# CC3200 register map
Vendor: Texas Instruments; Series: SimpleLink; File version: 1.0
CPU: CM4 r0p1, little endian, MPU, no FPU, 3 interrupt priority bits
Registers are 32-bit, read-write, reset 0x0 unless marked. A register's access mark holds for its fields unless they carry their own. Offsets are from the block's base; [hi:lo] are bit positions; {n}, {i} and the like mark numbered series.

## SHAMD5
Base 0x44035000
0x00 ODIGEST_A — SHAMD5_ODIGEST_A
  [31:0] DATA_M
0x04 ODIGEST_B — SHAMD5_ODIGEST_B
  [31:0] DATA_M
0x08 ODIGEST_C — SHAMD5_ODIGEST_C
  [31:0] DATA_M
0x0C ODIGEST_D — SHAMD5_ODIGEST_D
  [31:0] DATA_M
0x10 ODIGEST_E — SHAMD5_ODIGEST_E
  [31:0] DATA_M
0x14 ODIGEST_F — SHAMD5_ODIGEST_F
  [31:0] DATA_M
0x18 ODIGEST_G — SHAMD5_ODIGEST_G
  [31:0] DATA_M
0x1C ODIGEST_H — SHAMD5_ODIGEST_H
  [31:0] DATA_M
0x20 IDIGEST_A — SHAMD5_IDIGEST_A
  [31:0] DATA_M
0x24 IDIGEST_B — SHAMD5_IDIGEST_B
  [31:0] DATA_M
0x28 IDIGEST_C — SHAMD5_IDIGEST_C
  [31:0] DATA_M
0x2C IDIGEST_D — SHAMD5_IDIGEST_D
  [31:0] DATA_M
0x30 IDIGEST_E — SHAMD5_IDIGEST_E
  [31:0] DATA_M
0x34 IDIGEST_F — SHAMD5_IDIGEST_F
  [31:0] DATA_M
0x38 IDIGEST_G — SHAMD5_IDIGEST_G
  [31:0] DATA_M
0x3C IDIGEST_H — SHAMD5_IDIGEST_H
  [31:0] DATA_M
0x40 DIGEST_COUNT — SHAMD5_DIGEST_COUNT
  [31:0] DATA_M
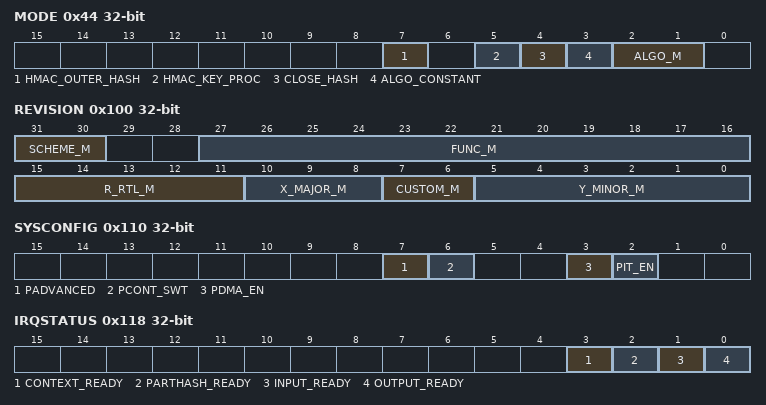
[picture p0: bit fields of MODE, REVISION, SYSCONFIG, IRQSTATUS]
0x44 MODE — SHAMD5_MODE
  [7] HMAC_OUTER_HASH — SHAMD5_MODE
  [5] HMAC_KEY_PROC — SHAMD5_MODE
  [4] CLOSE_HASH — SHAMD5_MODE
  [3] ALGO_CONSTANT — SHAMD5_MODE
  [2:1] ALGO_M — SHAMD5_MODE
0x48 LENGTH — SHAMD5_LENGTH
  [31:0] DATA_M
{0x80+4i} DATA{i}_IN (i=0..15) — SHAMD5_DATA{i}_IN
  [31:0] DATA{i}_IN_M
0x100 REVISION — SHAMD5_REVISION
  [31:30] SCHEME_M — SHAMD5_REVISION
  [27:16] FUNC_M — SHAMD5_REVISION
  [15:11] R_RTL_M — SHAMD5_REVISION
  [10:8] X_MAJOR_M — SHAMD5_REVISION
  [7:6] CUSTOM_M — SHAMD5_REVISION
  [5:0] Y_MINOR_M — SHAMD5_REVISION
0x110 SYSCONFIG — SHAMD5_SYSCONFIG
  [7] PADVANCED — SHAMD5_SYSCONFIG
  [6] PCONT_SWT — SHAMD5_SYSCONFIG
  [3] PDMA_EN — SHAMD5_SYSCONFIG
  [2] PIT_EN — SHAMD5_SYSCONFIG
0x114 SYSSTATUS — SHAMD5_SYSSTATUS
  [0] RESETDONE
0x118 IRQSTATUS — SHAMD5_IRQSTATUS
  [3] CONTEXT_READY — SHAMD5_IRQSTATUS
  [2] PARTHASH_READY — SHAMD5_IRQSTATUS
  [1] INPUT_READY — SHAMD5_IRQSTATUS
  [0] OUTPUT_READY — SHAMD5_IRQSTATUS
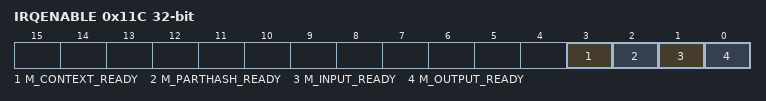
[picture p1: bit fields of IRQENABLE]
0x11C IRQENABLE — SHAMD5_IRQENABLE
  [3] M_CONTEXT_READY — SHAMD5_IRQENABLE
  [2] M_PARTHASH_READY — SHAMD5_IRQENABLE
  [1] M_INPUT_READY — SHAMD5_IRQENABLE
  [0] M_OUTPUT_READY — SHAMD5_IRQENABLE
0x200 HASH512_ODIGEST_A — SHAMD5_HASH512_ODIGEST_A
  [31:0] DATA_M
0x204 HASH512_ODIGEST_B — SHAMD5_HASH512_ODIGEST_B
  [31:0] DATA_M
0x208 HASH512_ODIGEST_C — SHAMD5_HASH512_ODIGEST_C
  [31:0] DATA_M
0x20C HASH512_ODIGEST_D — SHAMD5_HASH512_ODIGEST_D
  [31:0] DATA_M — SHAMD5_HASH512_ODIGEST_D
  [31:0] TA_M — SHAMD5_HASH512_ODIGEST_D
0x210 HASH512_ODIGEST_E — SHAMD5_HASH512_ODIGEST_E
  [31:0] DATA_M
0x214 HASH512_ODIGEST_F — SHAMD5_HASH512_ODIGEST_F
  [31:0] DATA_M
0x218 HASH512_ODIGEST_G — SHAMD5_HASH512_ODIGEST_G
  [31:0] DATA_M
0x21C HASH512_ODIGEST_H — SHAMD5_HASH512_ODIGEST_H
  [31:0] DATA_M
0x220 HASH512_ODIGEST_I — SHAMD5_HASH512_ODIGEST_I
  [31:0] DATA_M
0x224 HASH512_ODIGEST_J — SHAMD5_HASH512_ODIGEST_J
  [31:0] DATA_M
0x228 HASH512_ODIGEST_K — SHAMD5_HASH512_ODIGEST_K
  [31:0] DATA_M
0x22C HASH512_ODIGEST_L — SHAMD5_HASH512_ODIGEST_L
  [31:0] DATA_M
0x230 HASH512_ODIGEST_M — SHAMD5_HASH512_ODIGEST_M
  [31:0] DATA_M
0x234 HASH512_ODIGEST_N — SHAMD5_HASH512_ODIGEST_N
  [31:0] DATA_M
0x238 HASH512_ODIGEST_O — SHAMD5_HASH512_ODIGEST_O
  [31:0] DATA_M
0x23C HASH512_ODIGEST_P — SHAMD5_HASH512_ODIGEST_P
0x240 HASH512_IDIGEST_A — SHAMD5_HASH512_IDIGEST_A
  [31:0] DATA_M
0x244 HASH512_IDIGEST_B — SHAMD5_HASH512_IDIGEST_B
  [31:0] DATA_M
0x248 HASH512_IDIGEST_C — SHAMD5_HASH512_IDIGEST_C
  [31:0] DATA_M
0x24C HASH512_IDIGEST_D — SHAMD5_HASH512_IDIGEST_D
  [31:0] DATA_M — SHAMD5_HASH512_IDIGEST_D
  [31:0] TA_M — SHAMD5_HASH512_IDIGEST_D
0x250 HASH512_IDIGEST_E — SHAMD5_HASH512_IDIGEST_E
  [31:0] DATA_M
0x254 HASH512_IDIGEST_F — SHAMD5_HASH512_IDIGEST_F
  [31:0] DATA_M
0x258 HASH512_IDIGEST_G — SHAMD5_HASH512_IDIGEST_G
  [31:0] DATA_M
0x25C HASH512_IDIGEST_H — SHAMD5_HASH512_IDIGEST_H
  [31:0] DATA_M
0x260 HASH512_IDIGEST_I — SHAMD5_HASH512_IDIGEST_I
  [31:0] DATA_M
0x264 HASH512_IDIGEST_J — SHAMD5_HASH512_IDIGEST_J
  [31:0] DATA_M
0x268 HASH512_IDIGEST_K — SHAMD5_HASH512_IDIGEST_K
  [31:0] DATA_M
0x26C HASH512_IDIGEST_L — SHAMD5_HASH512_IDIGEST_L
  [31:0] DATA_M
0x270 HASH512_IDIGEST_M — SHAMD5_HASH512_IDIGEST_M
  [31:0] DATA_M
0x274 HASH512_IDIGEST_N — SHAMD5_HASH512_IDIGEST_N
  [31:0] DATA_M
0x278 HASH512_IDIGEST_O — SHAMD5_HASH512_IDIGEST_O
  [31:0] DATA_M
0x27C HASH512_IDIGEST_P — SHAMD5_HASH512_IDIGEST_P
0x280 HASH512_DIGEST_COUNT — SHAMD5_HASH512_DIGEST_COUNT
  [31:0] DATA_M
0x284 HASH512_MODE — SHAMD5_HASH512_MODE
  [31:0] DATA_M
0x288 HASH512_LENGTH — SHAMD5_HASH512_LENGTH
  [31:0] DATA_M
